# MCU_ADC0_ECC register map
Vendor: Texas Instruments
Peripheral module from a debugger description file (folder J7VCL).
Registers are 32-bit, access not given, reset 0x0 unless marked. A register's access mark holds for its fields unless they carry their own. Offsets are as the file gives them; lines under a group give offsets from that group; [hi:lo] are bit positions; {n}, {i} and the like mark numbered series; 'fields as' and 'values as' point back to an identical list; <NAME> marks a mode.

## MCU_ADC0_ECC
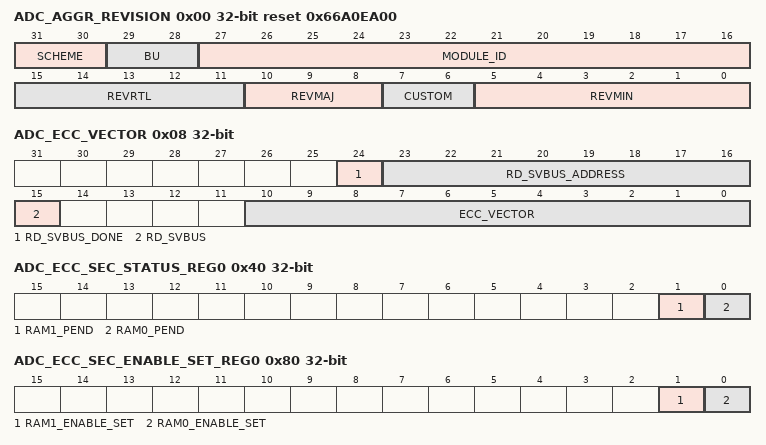
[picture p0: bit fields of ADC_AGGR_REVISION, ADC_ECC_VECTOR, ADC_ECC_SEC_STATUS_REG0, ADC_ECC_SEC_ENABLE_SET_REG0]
0x00 ADC_AGGR_REVISION ro reset 0x66A0EA00 — Revision parameters
  [31:30] SCHEME
  [29:28] BU
  [27:16] MODULE_ID
  [15:11] REVRTL — RTL version
  [10:8] REVMAJ — Major version
  [7:6] CUSTOM — Custom version
  [5:0] REVMIN — Minor version
0x08 ADC_ECC_VECTOR — ECC Vector Register
  [24] RD_SVBUS_DONE — Status to indicate if read on serial VBUS is complete (access RW1C)
  [23:16] RD_SVBUS_ADDRESS rw — Read address
  [15] RD_SVBUS — Write 1h = Trigger a read on the serial VBUS (access RW1S)
  [10:0] ECC_VECTOR rw — Value written to select the corresponding ECC RAM for
0x0C ADC_MISC_STATUS ro reset 0x2 — Misc Status
  [10:0] NUM_RAMS — Indicates the number of RAMS serviced by the ECC aggregator
0x3C ADC_ECC_SEC_EOI_REG — Register
  [0] EOI_WR — (access RW1S)
0x40 ADC_ECC_SEC_STATUS_REG0 — Interrupt Status Register 0
  [1] RAM1_PEND — Interrupt Pending Status for ram1_pend (access RW1S)
  [0] RAM0_PEND — Interrupt Pending Status for ram0_pend (access RW1S)
0x80 ADC_ECC_SEC_ENABLE_SET_REG0 — Interrupt Enable Set Register 0
  [1] RAM1_ENABLE_SET — Interrupt Enable Set Register for ram1_pend (access RW1S)
  [0] RAM0_ENABLE_SET — Interrupt Enable Set Register for ram0_pend (access RW1S)
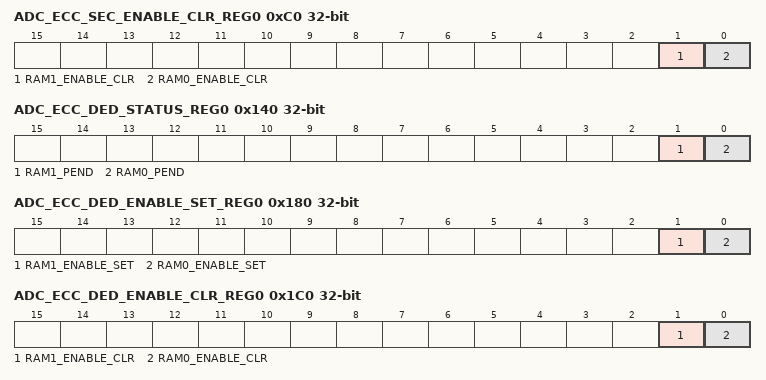
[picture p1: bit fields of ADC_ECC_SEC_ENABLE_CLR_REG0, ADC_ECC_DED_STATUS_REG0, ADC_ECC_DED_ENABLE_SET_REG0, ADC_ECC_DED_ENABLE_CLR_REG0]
0xC0 ADC_ECC_SEC_ENABLE_CLR_REG0 — Interrupt Enable Clear Register 0
  [1] RAM1_ENABLE_CLR — Interrupt Enable Clear Register for ram1_pend (access RW1C)
  [0] RAM0_ENABLE_CLR — Interrupt Enable Clear Register for ram0_pend (access RW1C)
0x13C ADC_ECC_DED_EOI_REG — Register
  [0] EOI_WR — (access RW1S)
0x140 ADC_ECC_DED_STATUS_REG0 — Interrupt Status Register 0
  fields as ADC_ECC_SEC_STATUS_REG0
0x180 ADC_ECC_DED_ENABLE_SET_REG0 — Interrupt Enable Set Register 0
  fields as ADC_ECC_SEC_ENABLE_SET_REG0
0x1C0 ADC_ECC_DED_ENABLE_CLR_REG0 — Interrupt Enable Clear Register 0
  fields as ADC_ECC_SEC_ENABLE_CLR_REG0
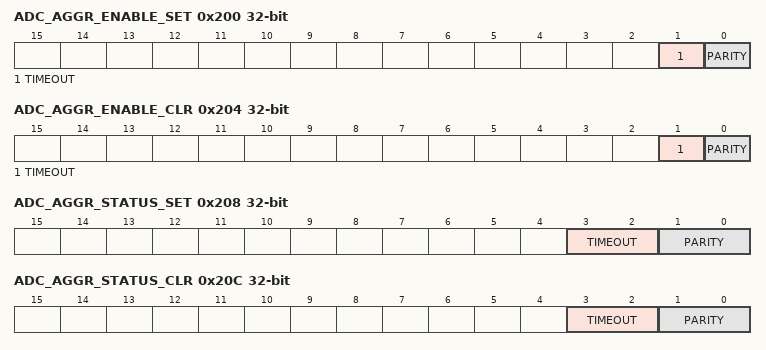
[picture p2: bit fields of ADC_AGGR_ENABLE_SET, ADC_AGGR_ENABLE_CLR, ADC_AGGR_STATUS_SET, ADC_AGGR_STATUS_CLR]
0x200 ADC_AGGR_ENABLE_SET — Return to the . AGGR interrupt enable set Register
  [1] TIMEOUT — interrupt enable set for svbus timeout errors (access RW1S)
  [0] PARITY — interrupt enable set for parity errors (access RW1S)
0x204 ADC_AGGR_ENABLE_CLR — Return to the . AGGR interrupt enable clear Register
  [1] TIMEOUT — interrupt enable clear for svbus timeout errors (access RW1C)
  [0] PARITY — interrupt enable clear for parity errors (access RW1C)
0x208 ADC_AGGR_STATUS_SET — Return to the . AGGR interrupt status set Register
  [3:2] TIMEOUT — interrupt status set for svbus timeout errors (access RWincr)
  [1:0] PARITY — interrupt status set for parity errors (access RWincr)
0x20C ADC_AGGR_STATUS_CLR — Return to the . AGGR interrupt status clear Register
  [3:2] TIMEOUT — interrupt status clear for svbus timeout errors (access RWdecr)
  [1:0] PARITY — interrupt status clear for parity errors (access RWdecr)
